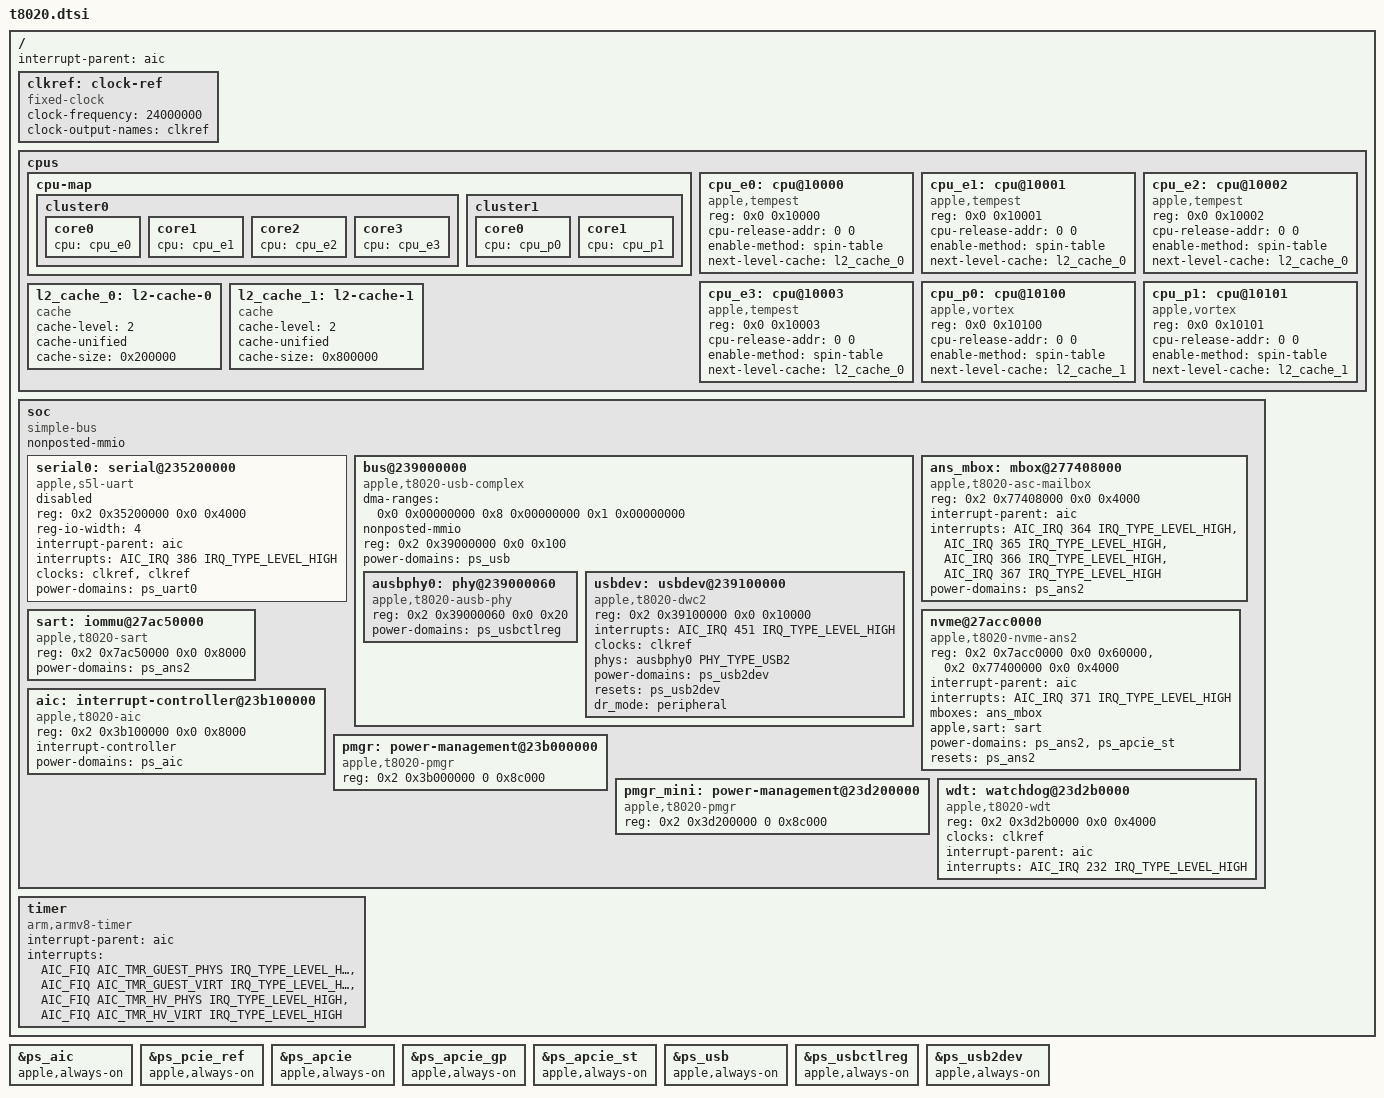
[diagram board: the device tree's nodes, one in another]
// SPDX-License-Identifier: GPL-2.0+ OR MIT
/*
 * Apple T8020 "A12" SoC
 *
 * Other names: H11
 *
 * Every address and interrupt number here was read out of the DeviceTree
 * shipped in the iPhone11,2 IPSW (see tools/iosdt.py), not guessed from T8015.
 * The arm-io ranges property maps child 0x0 to parent 0x200000000, so a
 * peripheral offset of 0x35200000 is absolute address 0x235200000.
 *
 * This is deliberately a bring-up subset: enough for a console and an
 * initramfs shell, nothing more. Blocks left out on purpose, with the reason:
 *
 *   cpufreq / OPP tables  Cluster controllers live at 0x210e20000 (E) and
 *                         0x211e20000 (P), but the A12 operating points are
 *                         not measured yet and wrong ones hang the cluster.
 *   pinctrl, i2c          Not needed to reach a shell.
 *
 * Copyright (c) 2026, kiki <kieran@lavato.net>
 */

#include <dt-bindings/interrupt-controller/apple-aic.h>
#include <dt-bindings/interrupt-controller/irq.h>
#include <dt-bindings/phy/phy.h>

/ {
	interrupt-parent = <&aic>;
	#address-cells = <2>;
	#size-cells = <2>;

	clkref: clock-ref {
		compatible = "fixed-clock";
		#clock-cells = <0>;
		clock-frequency = <24000000>;
		clock-output-names = "clkref";
	};

	cpus {
		#address-cells = <2>;
		#size-cells = <0>;

		cpu-map {
			cluster0 {
				core0 {
					cpu = <&cpu_e0>;
				};
				core1 {
					cpu = <&cpu_e1>;
				};
				core2 {
					cpu = <&cpu_e2>;
				};
				core3 {
					cpu = <&cpu_e3>;
				};
			};

			cluster1 {
				core0 {
					cpu = <&cpu_p0>;
				};
				core1 {
					cpu = <&cpu_p1>;
				};
			};
		};

		/*
		 * These must equal MPIDR_EL1 & 0xFFFFFF, which is what m1n1's
		 * dt_set_cpus matches against. The ADT's reg is not that value:
		 * it reports 0 for cpu0 and 256 for cpu4, missing the Aff2 bit.
		 * The boot CPU reported MPIDR 0x80010100, so the real affinity
		 * for cluster 1 core 0 is 0x10100, and the ADT values are the
		 * same numbers with 0x10000 missing. Get this wrong and m1n1
		 * prunes every CPU node, including the one it is running on,
		 * leaving Linux a device tree with no CPUs at all.
		 */
		cpu_e0: cpu@10000 {
			compatible = "apple,tempest";
			reg = <0x0 0x10000>;
			cpu-release-addr = <0 0>; /* To be filled by loader */
			enable-method = "spin-table";
			device_type = "cpu";
			next-level-cache = <&l2_cache_0>;
		};

		cpu_e1: cpu@10001 {
			compatible = "apple,tempest";
			reg = <0x0 0x10001>;
			cpu-release-addr = <0 0>; /* To be filled by loader */
			enable-method = "spin-table";
			device_type = "cpu";
			next-level-cache = <&l2_cache_0>;
		};

		cpu_e2: cpu@10002 {
			compatible = "apple,tempest";
			reg = <0x0 0x10002>;
			cpu-release-addr = <0 0>; /* To be filled by loader */
			enable-method = "spin-table";
			device_type = "cpu";
			next-level-cache = <&l2_cache_0>;
		};

		cpu_e3: cpu@10003 {
			compatible = "apple,tempest";
			reg = <0x0 0x10003>;
			cpu-release-addr = <0 0>; /* To be filled by loader */
			enable-method = "spin-table";
			device_type = "cpu";
			next-level-cache = <&l2_cache_0>;
		};

		cpu_p0: cpu@10100 {
			compatible = "apple,vortex";
			reg = <0x0 0x10100>;
			cpu-release-addr = <0 0>; /* To be filled by loader */
			enable-method = "spin-table";
			device_type = "cpu";
			next-level-cache = <&l2_cache_1>;
		};

		cpu_p1: cpu@10101 {
			compatible = "apple,vortex";
			reg = <0x0 0x10101>;
			cpu-release-addr = <0 0>; /* To be filled by loader */
			enable-method = "spin-table";
			device_type = "cpu";
			next-level-cache = <&l2_cache_1>;
		};

		/* Sizes come from the l2-cache-size property in the iOS DeviceTree. */
		l2_cache_0: l2-cache-0 {
			compatible = "cache";
			cache-level = <2>;
			cache-unified;
			cache-size = <0x200000>;
		};

		l2_cache_1: l2-cache-1 {
			compatible = "cache";
			cache-level = <2>;
			cache-unified;
			cache-size = <0x800000>;
		};
	};

	soc {
		compatible = "simple-bus";
		#address-cells = <2>;
		#size-cells = <2>;
		nonposted-mmio;
		ranges;

		/* iBoot calls this one debug-console and leaves it running. */
		serial0: serial@235200000 {
			compatible = "apple,s5l-uart";
			reg = <0x2 0x35200000 0x0 0x4000>;
			reg-io-width = <4>;
			interrupt-parent = <&aic>;
			interrupts = <AIC_IRQ 386 IRQ_TYPE_LEVEL_HIGH>;
			/* Use the bootloader-enabled clocks for now. */
			clocks = <&clkref>, <&clkref>;
			clock-names = "uart", "clk_uart_baud0";
			power-domains = <&ps_uart0>;
			status = "disabled";
		};

		/*
		 * USB device mode. This is what gives an interactive shell:
		 * the initramfs brings up a CDC-ACM gadget, which shows up as
		 * /dev/ttyACM0 on the host. Without it the framebuffer console
		 * can print but you have nothing to type on.
		 *
		 * dma-ranges maps DMA address 0 to the start of DRAM, which is
		 * the same thing T8015 does and assumes the USB DART is left in
		 * bypass. If DMA is where this falls over, that assumption is
		 * the first thing to check: the ADT has a dart-usb at
		 * 0x239900000 with interrupt 454 that this tree ignores.
		 */
		bus@239000000 {
			compatible = "apple,t8020-usb-complex", "simple-pm-bus";
			#address-cells = <2>;
			#size-cells = <2>;
			dma-ranges = <0x0 0x00000000 0x8 0x00000000 0x1 0x00000000>;

			/*
			 * of_mmio_is_nonposted() only looks at the node and its
			 * immediate parent, so the one on the soc node does not
			 * reach anything a bus further down. Without it here the
			 * PHY and dwc2 are mapped with ioremap() instead of
			 * ioremap_np(), and dwc2 then answers every read while
			 * dropping every write. Upstream repeats this property
			 * on the same bus for every A series SoC.
			 */
			nonposted-mmio;
			ranges;

			reg = <0x2 0x39000000 0x0 0x100>;
			power-domains = <&ps_usb>;

			ausbphy0: phy@239000060 {
				compatible = "apple,t8020-ausb-phy", "apple,ausb-phy";
				reg = <0x2 0x39000060 0x0 0x20>;
				power-domains = <&ps_usbctlreg>;
				#phy-cells = <1>;
				/* Tunables to be filled by loader */
			};

			usbdev: usbdev@239100000 {
				compatible = "apple,t8020-dwc2", "apple,dwc2";
				reg = <0x2 0x39100000 0x0 0x10000>;
				interrupts = <AIC_IRQ 451 IRQ_TYPE_LEVEL_HIGH>;
				clocks = <&clkref>;
				clock-names = "otg";
				phys = <&ausbphy0 PHY_TYPE_USB2>;
				phy-names = "usb2-phy";
				power-domains = <&ps_usb2dev>;
				resets = <&ps_usb2dev>;
				dr_mode = "peripheral";
			};
		};

		/*
		 * NVMe, which on this SoC means the ANS2 coprocessor rather
		 * than a PCIe controller. Every number here comes from
		 * /arm-io/ans and /arm-io/sart-ans in the IPSW DeviceTree.
		 *
		 * The ADT gives /arm-io/ans nine reg ranges. Two are wanted:
		 * index 0 is the ASC wrapper and index 3 is the NVMe register
		 * block. The wrapper carries both the mailbox, at +0x8000, and
		 * the coprocessor control register at +0x44, which is the
		 * arrangement T8103 uses rather than the split one T8015 has.
		 * Confirmed on the hardware: writing bit 4 of 0x277400044 starts
		 * ANS and it puts a message in the inbound queue.
		 *
		 * The ADT also lists a lone four byte range at 0x27ad20044, which
		 * looks like a second copy of the same control register and
		 * accepts the write without starting anything. Pointing the node
		 * at it instead probes cleanly and then fails with "ANS did not
		 * boot". It is a decoy.
		 *
		 * The ADT lists five interrupts and says nvme-interrupt-idx is
		 * 4, so 371 is NVMe and the first four belong to the mailbox.
		 * The ADT order is 365, 364, 367, 366, which is two descending
		 * pairs rather than the order the binding wants. Read each pair
		 * as (not-empty, empty) and it comes out ascending, which is
		 * also how every other Apple SoC spells it, so that is what is
		 * used below. Taking the ADT order literally instead puts
		 * recv-not-empty on 366 and no mailbox interrupt ever arrives.
		 *
		 * The mailbox is the T8015 kind, not the v4 kind, even though
		 * the control register sits where T8103 puts it. The two
		 * layouts put their queue control registers in different
		 * places, 0x108 and 0x10c against 0x110 and 0x114, and on this
		 * SoC only the first pair is live: 0x108 reads 0x00020001 with
		 * the empty bit set, 0x110 and 0x114 read zero always. Claiming
		 * v4 here makes the driver poll two registers that never
		 * change, so the RTKit handshake times out and NVMe fails with
		 * "ANS did not boot" even though the coprocessor started.
		 */
		ans_mbox: mbox@277408000 {
			compatible = "apple,t8020-asc-mailbox", "apple,t8015-asc-mailbox";
			reg = <0x2 0x77408000 0x0 0x4000>;
			interrupt-parent = <&aic>;
			interrupts = <AIC_IRQ 364 IRQ_TYPE_LEVEL_HIGH>,
				     <AIC_IRQ 365 IRQ_TYPE_LEVEL_HIGH>,
				     <AIC_IRQ 366 IRQ_TYPE_LEVEL_HIGH>,
				     <AIC_IRQ 367 IRQ_TYPE_LEVEL_HIGH>;
			interrupt-names = "send-empty", "send-not-empty",
					  "recv-empty", "recv-not-empty";
			#mbox-cells = <0>;
			power-domains = <&ps_ans2>;
		};

		/*
		 * The ADT says sart-version = 1, which neither Linux nor m1n1
		 * has a case for: both know 0, 2 and 3 only. v0 and v2 share
		 * their register offsets and differ only in field widths, so
		 * the question is which one v1 resembles. The entries iBoot
		 * leaves behind answer it: one reads config 0x2f000004, and
		 * bit 29 is set, which does not fit v0's five bit flags field
		 * at 28:24 but does fit v2's eight bit field at 31:24. The size
		 * field decodes to 4 pages either way.
		 *
		 * v2 is also what gets furthest in practice: the coprocessor
		 * DMAs its syslog back, so the allowed regions it adds plainly
		 * work. Both v0 and v2 were first compared while the PCIe
		 * reference clock was still being switched off underneath
		 * them, so that earlier comparison proved nothing and was
		 * redone afterwards.
		 */
		sart: iommu@27ac50000 {
			compatible = "apple,t8020-sart";
			reg = <0x2 0x7ac50000 0x0 0x8000>;
			power-domains = <&ps_ans2>;
		};

		/*
		 * The driver has one variant for T8015, with no LSQ NVMMU and a
		 * queue depth of 16, and one for T8103 with both. T8015 is the
		 * one that gets furthest: the firmware boots, logs "boot mode
		 * normal" and starts reading NAND context. Claiming T8103
		 * instead goes back to crashing early.
		 *
		 * Treat that comparison as weak evidence though. The T8103 run
		 * reported the same PC and FAR as a crash from two boots
		 * earlier, so ANS looks like it keeps its crashlog across a
		 * reset and RTKit replays whatever it finds. Any single boot's
		 * crash dump may belong to a previous one.
		 */
		nvme@27acc0000 {
			compatible = "apple,t8020-nvme-ans2";
			reg = <0x2 0x7acc0000 0x0 0x60000>,
			      <0x2 0x77400000 0x0 0x4000>;
			reg-names = "nvme", "ans";
			interrupt-parent = <&aic>;
			interrupts = <AIC_IRQ 371 IRQ_TYPE_LEVEL_HIGH>;
			mboxes = <&ans_mbox>;
			apple,sart = <&sart>;
			power-domains = <&ps_ans2>, <&ps_apcie_st>;
			power-domain-names = "ans", "apcie0";
			resets = <&ps_ans2>;
		};

		aic: interrupt-controller@23b100000 {
			compatible = "apple,t8020-aic", "apple,aic";
			reg = <0x2 0x3b100000 0x0 0x8000>;
			#interrupt-cells = <3>;
			interrupt-controller;
			power-domains = <&ps_aic>;
		};

		pmgr: power-management@23b000000 {
			compatible = "apple,t8020-pmgr", "apple,pmgr", "syscon", "simple-mfd";
			#address-cells = <1>;
			#size-cells = <1>;

			reg = <0x2 0x3b000000 0 0x8c000>;
		};

		pmgr_mini: power-management@23d200000 {
			compatible = "apple,t8020-pmgr", "apple,pmgr", "syscon", "simple-mfd";
			#address-cells = <1>;
			#size-cells = <1>;

			reg = <0x2 0x3d200000 0 0x8c000>;
		};

		wdt: watchdog@23d2b0000 {
			compatible = "apple,t8020-wdt", "apple,wdt";
			reg = <0x2 0x3d2b0000 0x0 0x4000>;
			clocks = <&clkref>;
			interrupt-parent = <&aic>;
			interrupts = <AIC_IRQ 232 IRQ_TYPE_LEVEL_HIGH>;
		};
	};

	timer {
		compatible = "arm,armv8-timer";
		interrupt-parent = <&aic>;
		interrupt-names = "phys", "virt", "hyp-phys", "hyp-virt";
		/* Unlike A11, the A12 does implement EL2, so wire the HV timers too. */
		interrupts = <AIC_FIQ AIC_TMR_GUEST_PHYS IRQ_TYPE_LEVEL_HIGH>,
			     <AIC_FIQ AIC_TMR_GUEST_VIRT IRQ_TYPE_LEVEL_HIGH>,
			     <AIC_FIQ AIC_TMR_HV_PHYS IRQ_TYPE_LEVEL_HIGH>,
			     <AIC_FIQ AIC_TMR_HV_VIRT IRQ_TYPE_LEVEL_HIGH>;
	};
};

#include "t8020-pmgr.dtsi"

/*
 * Keep the interrupt controller powered.
 *
 * Nothing in Linux ever claims this domain. The AIC driver comes up through
 * IRQCHIP_DECLARE, which runs long before the driver model exists and never
 * creates a device, so there is no consumer for genpd to count. "PM: genpd:
 * Disabling unused power domains" then switches the controller off, and from
 * that point no interrupt is delivered and any read of an AIC register hangs
 * the core with no oops and no further output. The architected timer keeps
 * running through all of it because it is a core local FIQ that does not go
 * through AIC at all, so the boot reaches a shell looking healthy.
 *
 * Upstream marks this one always-on as a core device. The annotation is
 * missing here because t8020-pmgr.dtsi is generated by "make pmgr" from the
 * iOS DeviceTree, which has no equivalent property.
 */
&ps_aic {
	apple,always-on;
};

/*
 * Keep the PCIe reference clock powered.
 *
 * NVMe lives behind ANS2, and ANS2 reaches the storage link through the APCIe
 * block at 0x600080000. Nothing in this tree claims ps_pcie_ref: it has no
 * parent domain, and the nvme node names ps_ans2 and ps_apcie_st, whose own
 * parents genpd pulls up for it. So ps_pcie_ref is left with no users and
 * genpd switches it off, exactly as it did to the interrupt controller.
 *
 * The ANS firmware then takes an SError on 0x600084000, which is inside the
 * APCIe register window, and the driver reports "ANS did not boot" with a
 * crashlog whose FAR is that address.
 */
&ps_pcie_ref {
	apple,always-on;
};

/*
 * Keep the whole APCIe complex powered.
 *
 * The reference clock alone was not enough: the SError on 0x600084000 came
 * back intermittently, so one boot in two or three still lost the window
 * before ANS reached it. There is no apcie node in this tree, which means no
 * driver owns any of these domains. ps_apcie_st is the one the nvme node
 * names, and genpd pulls its parents ps_apcie and ps_imx up with it, but
 * ps_apcie_gp has no user at all and the whole set is at genpd's mercy for
 * ordering. Pinning all three takes the power manager out of the question;
 * iBoot has already trained the link by the time Linux starts, so nothing
 * here needs to bring the complex up, only to leave it alone.
 */
&ps_apcie {
	apple,always-on;
};

&ps_apcie_gp {
	apple,always-on;
};

&ps_apcie_st {
	apple,always-on;
};

/*
 * Keep the USB domains powered.
 *
 * dwc2 reads this controller fine but every write to it is dropped: GINTMSK,
 * DIEPMSK, GAHBCFG and DCTL all read back unchanged immediately after being
 * written, and GINTMSK and DIEPMSK read 0 even though the driver's own init
 * wrote them. Registers that keep their contents for reads but will not latch
 * a write are a block with no clock, which is what these domains gate.
 *
 * Nothing holds them up. drivers/usb/dwc2/platform.c uses no runtime PM at
 * all, and it calls dwc2_lowlevel_hw_disable() at the end of probe when
 * dr_mode is peripheral, so the domains are left to genpd, which powers down
 * whatever nothing has claimed.
 *
 * These overrides go here rather than in t8020-pmgr.dtsi because that file is
 * generated by "make pmgr" and edits to it do not survive.
 */
&ps_usb {
	apple,always-on;
};

&ps_usbctlreg {
	apple,always-on;
};

&ps_usb2dev {
	apple,always-on;
};
